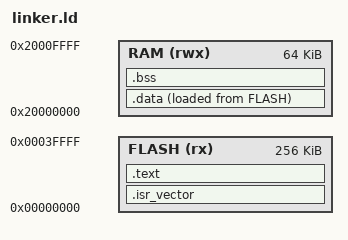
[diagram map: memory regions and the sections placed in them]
MEMORY
{
    FLASH (rx)  : ORIGIN = 0x00000000, LENGTH = 256K
    RAM   (rwx) : ORIGIN = 0x20000000, LENGTH = 64K
}

_estack = ORIGIN(RAM) + LENGTH(RAM);


ENTRY(Reset_Handler)

SECTIONS
{
    .isr_vector : { KEEP(*(.isr_vector)) } > FLASH

    .text :
    {
        . = ALIGN(4);
        *(.text*)
        *(.rodata*)
        . = ALIGN(4);
        _etext = .;
    } > FLASH

    _sidata = LOADADDR(.data);

    .data :
    {
        . = ALIGN(4);
        _sdata = .;
        *(.data*)
        . = ALIGN(4);
        _edata = .;
    } > RAM AT > FLASH

    .bss :
    {
        . = ALIGN(4);
        _sbss = .;
        *(.bss*)
        *(COMMON)
        . = ALIGN(4);
        _ebss = .;
    } > RAM
}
